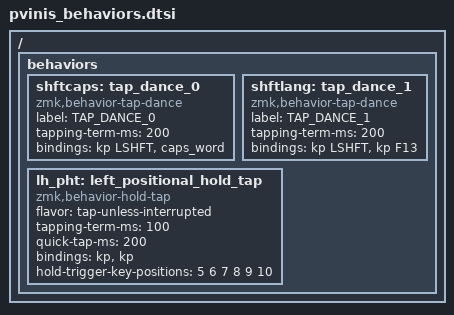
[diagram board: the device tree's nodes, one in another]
// shared behaviors for all keyboards
/ {
	behaviors {
		// tap dance
		shftcaps: tap_dance_0 {
			compatible = "zmk,behavior-tap-dance";
			label = "TAP_DANCE_0";
			#binding-cells = <0>;
			tapping-term-ms = <200>;
			bindings = <&kp LSHFT>, <&caps_word>;
		};
		shftlang: tap_dance_1 {
			compatible = "zmk,behavior-tap-dance";
			label = "TAP_DANCE_1";
			#binding-cells = <0>;
			tapping-term-ms = <200>;
			bindings = <&kp LSHFT>, <&kp F13>;
		};
		lh_pht: left_positional_hold_tap {
			compatible = "zmk,behavior-hold-tap";
			#binding-cells = <2>;
			flavor = "tap-unless-interrupted";
			tapping-term-ms = <100>;// <---[[produces tap if held longer than tapping-term-ms]]
			quick-tap-ms = <200>;
			bindings = <&kp>, <&kp>;
			hold-trigger-key-positions = <5 6 7 8 9 10>;// <---[[right-hand keys]]
		};
	};
};
